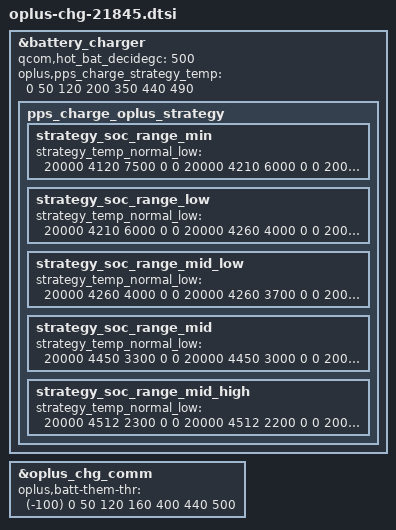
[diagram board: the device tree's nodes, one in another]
//ifdef OPLUS_FEATURE_CHG_BASIC

#include "oplus-chg-21841.dtsi"

&battery_charger {
	qcom,hot_bat_decidegc = <500>;
	oplus,pps_charge_strategy_temp = <0 50 120 200 350 440 490>;
	pps_charge_oplus_strategy {
		strategy_soc_range_min {
			strategy_temp_normal_low =	<20000 4120 7500 0 0
							 20000 4210 6000 0 0
							 20000 4260 4000 0 0
							 20000 4260 3700 0 0
							 20000 4280 3400 0 0
							 20000 4450 3300 0 0
							 20000 4450 3000 0 0
							 20000 4450 2700 0 0
							 20000 4480 2400 0 0
							 20000 4512 2300 0 0
							 20000 4512 2200 0 0
							 20000 4512 2100 0 0
							 20000 4512 2000 0 0
							 20000 4512 1900 0 0
							 20000 4512 1800 0 0
							 20000 4512 1700 0 0
							 20000 4512 1600 0 0
							 20000 4512 1500 0 0
							 20000 4512 1400 0 0
							 20000 4512 1300 0 0
							 20000 4512 1200 0 0
							 20000 4512 1100 0 0
							 20000 4512 1000 0 0
							 20000 4512 900 0 0
							 20000 4520 800 1 0>;
		};
		strategy_soc_range_low {
			strategy_temp_normal_low =	<20000 4210 6000 0 0
							 20000 4260 4000 0 0
							 20000 4260 3700 0 0
							 20000 4280 3400 0 0
							 20000 4450 3300 0 0
							 20000 4450 3000 0 0
							 20000 4450 2700 0 0
							 20000 4480 2400 0 0
							 20000 4512 2300 0 0
							 20000 4512 2200 0 0
							 20000 4512 2100 0 0
							 20000 4512 2000 0 0
							 20000 4512 1900 0 0
							 20000 4512 1800 0 0
							 20000 4512 1700 0 0
							 20000 4512 1600 0 0
							 20000 4512 1500 0 0
							 20000 4512 1400 0 0
							 20000 4512 1300 0 0
							 20000 4512 1200 0 0
							 20000 4512 1100 0 0
							 20000 4512 1000 0 0
							 20000 4512 900 0 0
							 20000 4520 800 1 0>;
		};
		strategy_soc_range_mid_low {
			strategy_temp_normal_low =	<20000 4260 4000 0 0
							 20000 4260 3700 0 0
							 20000 4280 3400 0 0
							 20000 4450 3300 0 0
							 20000 4450 3000 0 0
							 20000 4450 2700 0 0
							 20000 4480 2400 0 0
							 20000 4512 2300 0 0
							 20000 4512 2200 0 0
							 20000 4512 2100 0 0
							 20000 4512 2000 0 0
							 20000 4512 1900 0 0
							 20000 4512 1800 0 0
							 20000 4512 1700 0 0
							 20000 4512 1600 0 0
							 20000 4512 1500 0 0
							 20000 4512 1400 0 0
							 20000 4512 1300 0 0
							 20000 4512 1200 0 0
							 20000 4512 1100 0 0
							 20000 4512 1000 0 0
							 20000 4512 900 0 0
							 20000 4520 800 1 0>;
		};
		strategy_soc_range_mid {
			strategy_temp_normal_low =	<20000 4450 3300 0 0
							 20000 4450 3000 0 0
							 20000 4450 2700 0 0
							 20000 4480 2400 0 0
							 20000 4512 2300 0 0
							 20000 4512 2200 0 0
							 20000 4512 2100 0 0
							 20000 4512 2000 0 0
							 20000 4512 1900 0 0
							 20000 4512 1800 0 0
							 20000 4512 1700 0 0
							 20000 4512 1600 0 0
							 20000 4512 1500 0 0
							 20000 4512 1400 0 0
							 20000 4512 1300 0 0
							 20000 4512 1200 0 0
							 20000 4512 1100 0 0
							 20000 4512 1000 0 0
							 20000 4512 900 0 0
							 20000 4520 800 1 0>;
		};
		strategy_soc_range_mid_high {
			strategy_temp_normal_low =	<20000 4512 2300 0 0
							 20000 4512 2200 0 0
							 20000 4512 2100 0 0
							 20000 4512 2000 0 0
							 20000 4512 1900 0 0
							 20000 4512 1800 0 0
							 20000 4512 1700 0 0
							 20000 4512 1600 0 0
							 20000 4512 1500 0 0
							 20000 4512 1400 0 0
							 20000 4512 1300 0 0
							 20000 4512 1200 0 0
							 20000 4512 1100 0 0
							 20000 4512 1000 0 0
							 20000 4512 900 0 0
							 20000 4520 800 1 0>;
		};
	};
};

&oplus_chg_comm{
	oplus,batt-them-thr = <(-100) 0 50 120 160 400 440 500>;//tbat
};

//endif OPLUS_FEATURE_CHG_BASIC
